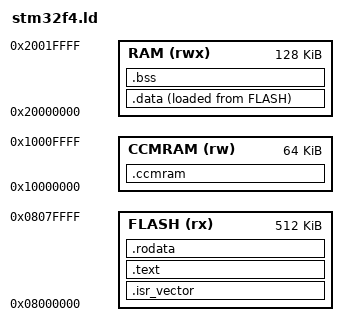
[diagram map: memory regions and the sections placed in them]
/* STM32F407 Linker Script - Sample */

ENTRY(Reset_Handler)

MEMORY
{
  FLASH (rx)  : ORIGIN = 0x08000000, LENGTH = 512K
  RAM   (rwx) : ORIGIN = 0x20000000, LENGTH = 128K
  CCMRAM (rw) : ORIGIN = 0x10000000, LENGTH = 64K
}

SECTIONS
{
  .isr_vector :
  {
    . = ALIGN(4);
    KEEP(*(.isr_vector))
    . = ALIGN(4);
  } > FLASH

  .text :
  {
    . = ALIGN(4);
    *(.text)
    *(.text*)
    *(.glue_7)
    *(.glue_7t)
    KEEP(*(.init))
    KEEP(*(.fini))
    . = ALIGN(4);
  } > FLASH

  .rodata :
  {
    . = ALIGN(4);
    *(.rodata)
    *(.rodata*)
    . = ALIGN(4);
  } > FLASH

  .data :
  {
    . = ALIGN(4);
    _sdata = .;
    *(.data)
    *(.data*)
    . = ALIGN(4);
    _edata = .;
  } > RAM AT> FLASH

  .bss :
  {
    . = ALIGN(4);
    _sbss = .;
    *(.bss)
    *(.bss*)
    *(COMMON)
    . = ALIGN(4);
    _ebss = .;
  } > RAM

  .ccmram :
  {
    . = ALIGN(4);
    *(.ccmram)
    *(.ccmram*)
    . = ALIGN(4);
  } > CCMRAM
}
